# STM32H7S3xx register map
File version: 1.0
Registers are 32-bit, read-write, reset 0x0 unless marked. A register's access mark holds for its fields unless they carry their own. Offsets are from the block's base; [hi:lo] are bit positions; {n}, {i} and the like mark numbered series; 'fields as' and 'values as' point back to an identical list.

## SBS — System configuration, boot and security controller
Base 0x58000400
0x00 BOOTSR — SBS Boot Status register
  [31:0] INITVTOR — Initial vector for Cortex-M7
0x10 HDPLCR — SBS Hide Protection Control register
  [7:0] INCR_HDPL — Increment HDPL
0x14 HDPLSR — SBS Hide Protection Status register
  [7:0] HDPL — Hide protection level
    180=Hide protection level 0; 81=Hide protection level 1; 138=Hide protection level 2; 111=Hide protection level 3
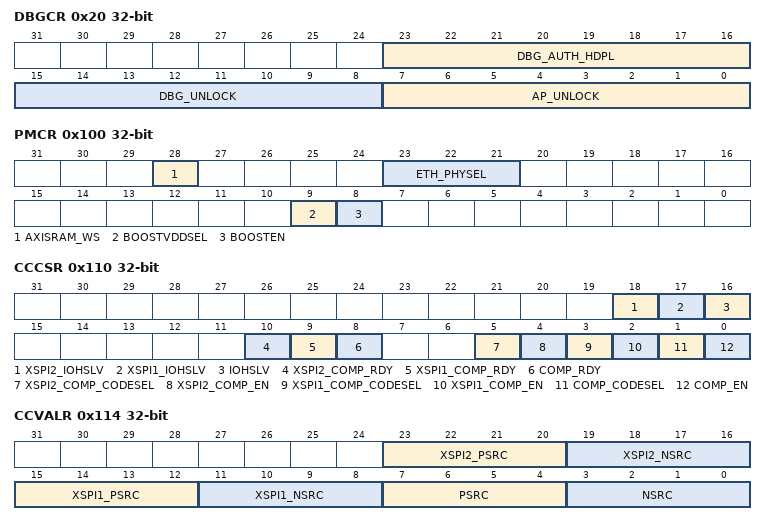
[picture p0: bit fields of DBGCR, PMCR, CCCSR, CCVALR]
0x20 DBGCR — SBS Debug Control register
  [23:16] DBG_AUTH_HDPL — Authenticated debug hide protection level
  [15:8] DBG_UNLOCK — Debug unlock
  [7:0] AP_UNLOCK — Access port unlock
0x24 DBGLOCKR — SBS Debug Lock register
  [7:0] DBGCFG_LOCK — Debug configuration lock
0x34 RSSCMDR — SBS RSS Command register
  [15:0] RSSCMD — RSS command
0x100 PMCR — SBS Product Mode & Config register
  [28] AXISRAM_WS — AXISRAM wait state
    0=NO_WS (No wait state added when accessing AXISRAM); 1=ONE_WS (One wait state added when accessing AXISRAM)
  [23:21] ETH_PHYSEL — Ethernet PHY interface selection
    0=GMII_MII (GMII or MII interface); 4=RMII (RMII interface)
  [9] BOOSTVDDSEL — Booster Vdd selection
    0=VDDA (Vdda selected as analog switch booster voltage supply); 1=VDD (Vdd selected as analog switch booster voltage supply)
  [8] BOOSTEN — Booster enable
0x104 FPUIMR — SBS FPU Interrupt Mask register
  [5:0] FPU_IE — All FPU interrupts enable
0x108 MESR — SBS Memory Erase Status register
  [0] MEF — Memory erase flag
0x110 CCCSR — SBS IO Compensation Cell Control and Status register
  [18] XSPI2_IOHSLV — XSPIM_P2 I/O high speed at low voltage
  [17] XSPI1_IOHSLV — XSPIM_P1 I/O high speed at low voltage
  [16] IOHSLV — I/O high speed at low voltage
  [10] XSPI2_COMP_RDY — XSPIM_P2 compensation cell ready
  [9] XSPI1_COMP_RDY — XSPIM_P1 compensation cell ready
  [8] COMP_RDY — Compensation cell ready
  [5] XSPI2_COMP_CODESEL — XSPIM_P2 compensation cell code selection
    0=CELL (Code applied to compensation cell from cell); 1=REG (Code applied to compensation cell from register)
  [4] XSPI2_COMP_EN — XSPIM_P2 compensation cell enable
  [3] XSPI1_COMP_CODESEL — XSPIM_P1 compensation cell code selection
    values as XSPI2_COMP_CODESEL
  [2] XSPI1_COMP_EN — XSPIM_P1 compensation cell enable
  [1] COMP_CODESEL — Compensation cell code selection
    values as XSPI2_COMP_CODESEL
  [0] COMP_EN — Compensation cell enable
0x114 CCVALR — SBS IO Compensation Cell Value register
  [23:20] XSPI2_PSRC — XSPIM_P2 PMOS transistors slew-rate compensation
  [19:16] XSPI2_NSRC — XSPIM_P2 NMOS transistors slew-rate compensation
  [15:12] XSPI1_PSRC — XSPIM_P1 PMOS transistors slew-rate compensation
  [11:8] XSPI1_NSRC — XSPIM_P1 NMOS transistors slew-rate compensation
  [7:4] PSRC — PMOS transistors slew-rate compensation
  [3:0] NSRC — NMOS transistors slew-rate compensation
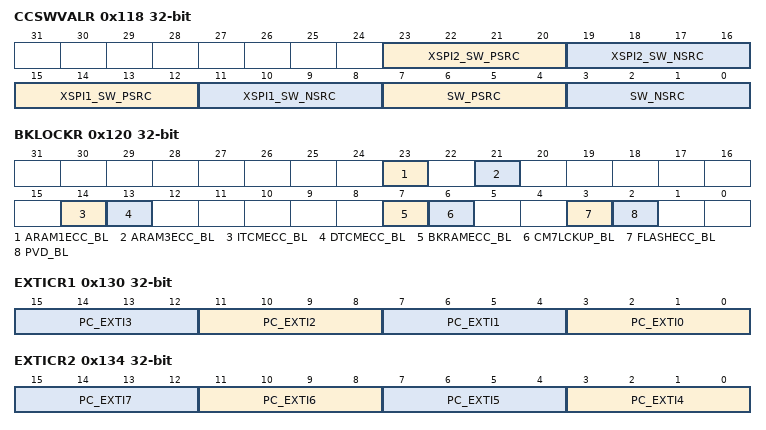
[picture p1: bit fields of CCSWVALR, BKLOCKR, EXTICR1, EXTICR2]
0x118 CCSWVALR — SBS IO Compensation Cell Software Value register
  [23:20] XSPI2_SW_PSRC — XSPIM_P2 software PMOS transistors slew-rate compensation
  [19:16] XSPI2_SW_NSRC — XSPIM_P2 software NMOS transistors slew-rate compensation
  [15:12] XSPI1_SW_PSRC — XSPIM_P1 software PMOS transistors slew-rate compensation
  [11:8] XSPI1_SW_NSRC — XSPIM_P1 software NMOS transistors slew-rate compensation
  [7:4] SW_PSRC — Software PMOS transistors slew-rate compensation
  [3:0] SW_NSRC — Software NMOS transistors slew-rate compensation
0x120 BKLOCKR — SBS Break Lockup register
  [23] ARAM1ECC_BL — AXIRAM1 ECC error break lock
  [21] ARAM3ECC_BL — AXIRAM3 ECC error break lock
  [14] ITCMECC_BL — ITCM ECC error break lock
  [13] DTCMECC_BL — DTCM ECC error break lock
  [7] BKRAMECC_BL — Backup RAM ECC error break lock
  [6] CM7LCKUP_BL — Cortex-M7 lockup break lock
  [3] FLASHECC_BL — Flash ECC error break lock
  [2] PVD_BL — PVD break lock
0x130 EXTICR1 — SBS External Interrupt Configuration registers
  [4n+3:4n] PC_EXTI{n} (n=0..3) — Port configuration EXTI {n}
0x134 EXTICR2 — SBS External Interrupt Configuration registers
  [4n-13:4n-16] PC_EXTI{n} (n=4..7) — Port configuration EXTI {n}
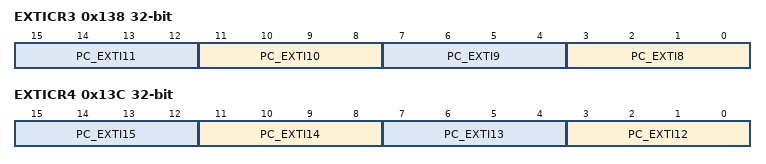
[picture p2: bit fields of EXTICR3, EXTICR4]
0x138 EXTICR3 — SBS External Interrupt Configuration registers
  [4n-29:4n-32] PC_EXTI{n} (n=8..11) — Port configuration EXTI {n}
0x13C EXTICR4 — SBS External Interrupt Configuration registers
  [4n-45:4n-48] PC_EXTI{n} (n=12..15) — Port configuration EXTI {n}
